# S32K322_M7 register map
Vendor: NXP Semiconductors; File version: 1.0
CPU: CM7 r0p1, little endian, MPU, FPU, VTOR, 4 interrupt priority bits
Registers are 32-bit, read-write, reset 0x0 unless marked. A register's access mark holds for its fields unless they carry their own. Offsets are from the block's base; [hi:lo] are bit positions; lines under a group give offsets from that group; {n}, {i} and the like mark numbered series.

## PIT_0 — PIT
Base 0x400B0000
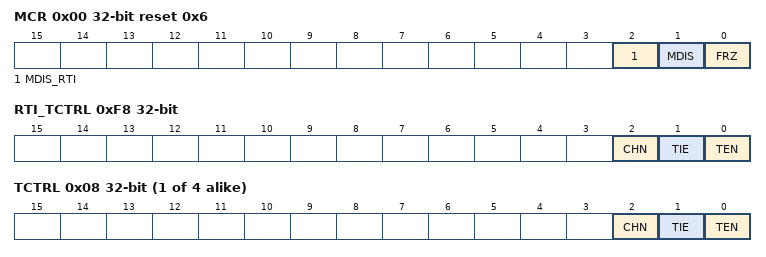
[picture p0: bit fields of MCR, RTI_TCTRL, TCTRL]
0x00 MCR reset 0x6 — PIT Module Control Register
  [2] MDIS_RTI — Module Disable for RTI
    0=t00221 (Clock for RTI timers is enabled); 1=t01881 (Clock for RTI timers is disabled)
  [1] MDIS — Module Disable for PIT
    0=t0301 (Clock for standard PIT timers is enabled.); 1=t00000111 (Clock for standard PIT timers is disabled.)
  [0] FRZ — Freeze
    0=t000001 (Timers continue to run in Debug mode.); 1=t0000011 (Timers are stopped in Debug mode.)
0xE0 LTMR64H ro — PIT Upper Lifetime Timer Register
  [31:0] LTH — Life Timer value
0xE4 LTMR64L ro — PIT Lower Lifetime Timer Register
  [31:0] LTL — Life Timer value
0xEC RTI_LDVAL_STAT write-clears — RTI Timer Load Value Sync Status Register
  [0] RT_STAT write-clears — RTI Timer Load Value Sync Status
    0=t00221112 (RTI_LDVAL register not loaded.); 1=t0022144 (RTI_LDVAL register updated with new value.)
0xF0 RTI_LDVAL — Timer Load Value Register
  [31:0] TSV — Timer Start Value
0xF4 RTI_CVAL ro — Current Timer Value Register
  [31:0] TVL — Current Timer Value
0xF8 RTI_TCTRL — Timer Control Register
  [2] CHN — Chain Mode
  [1] TIE — Timer Interrupt Enable
    0=t0661 (Interrupt requests from the RTI timers are disabled.); 1=t071 (Interrupt is requested whenever TIF is set.)
  [0] TEN — Timer Enable Bit
    0=t0041 (RTI timer is disabled.); 1=t061 (RTI timer is enabled.)
0xFC RTI_TFLG write-1-clears — Timer Flag Register
  [0] TIF write-1-clears — Timer Interrupt Flag
    0=t07321 (Time-out has not yet occurred.); 1=s4071 (Time-out has occurred.)
{0x100+0x10*i} TIMER[{i}] (i=0..3) group
  0x00 LDVAL — Timer Load Value Register
    [31:0] TSV — Timer Start Value
  0x04 CVAL ro — Current Timer Value Register
    [31:0] TVL — Current Timer Value
  0x08 TCTRL — Timer Control Register
    [2] CHN — Chain Mode
      0=timer0001 (Timer is not chained.); 1=timer0081 (Timer is chained to a previous timer. For example, for channel 2, if this field is set, Timer 2 is chained to Timer 1.)
    [1] TIE — Timer Interrupt Enable
      0=t0331 (Interrupt requests from Timer n are disabled.); 1=t077711 (Interrupt is requested whenever TIF is set.)
    [0] TEN — Timer Enable
      0=t02981 (Timer n is disabled.); 1=t008981 (Timer n is enabled.)
  0x0C TFLG write-1-clears — Timer Flag Register
    [0] TIF write-1-clears — Timer Interrupt Flag
      0=t0022331 (Timeout has not yet occurred.); 1=t0022332221 (Timeout has occurred.)

## PIT_1 — PIT
Base 0x400B4000
Same registers: PIT_2 0x402FC000
Registers as PIT_0, without LTMR64H, LTMR64L, RTI_LDVAL_STAT, RTI_LDVAL, RTI_CVAL, RTI_TCTRL, RTI_TFLG; these are added or differ:
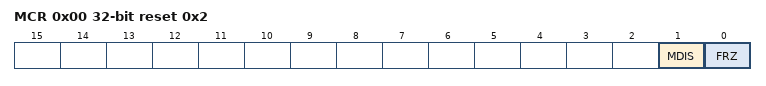
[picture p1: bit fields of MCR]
0x00 MCR reset 0x2 — PIT Module Control Register
  [1] MDIS — Module Disable for PIT
    0=t0301 (Clock for standard PIT timers is enabled.); 1=t00000111 (Clock for standard PIT timers is disabled.)
  [0] FRZ — Freeze
    0=t000001 (Timers continue to run in Debug mode.); 1=t0000011 (Timers are stopped in Debug mode.)

## AXBS_LITE — AXBS
Base 0x40200000
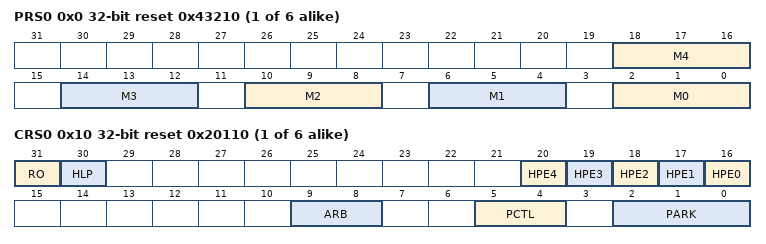
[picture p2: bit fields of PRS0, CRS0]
{0x0+0x100*i} PRS{i} reset 0x43210 (i=0..5) — Priority Slave Registers
  [all] fields
    0=This master has level 1 or highest priority when accessing the slave port; {v}=This master has level {v+1} priority when accessing the slave port (v=1..6); 7=This master has level 8 or lowest priority when accessing the slave port
  [4n+2:4n] M{n} (n=0..4) — Master {n} Priority
{0x10+0x100*i} CRS{i} reset 0x20110 (i=0..5) — Control Register
  [31] RO — Read Only
    0=The CRSn and PRSn registers are writeable; 1=The CRSn and PRSn registers are read-only and cannot be written (attempted writes have no effect on the registers and result in a bus error response)
  [30] HLP — Halt Low Priority
    0=The low-power mode request has the highest priority for arbitration on this slave port; 1=The low-power mode request has the lowest initial priority for arbitration on this slave port
  [n+16] HPE{n} (n=0..4) — High Priority Elevation {n}
    0=Master high-priority elevation for master {n}. is disabled on this slave port.; 1=Master high-priority elevation for master {n}. is enabled on this slave port.
  [9:8] ARB — Arbitration Mode
    0=Fixed priority; 1=Round-robin (rotating) priority
  [5:4] PCTL — Parking Control
    0=When no master makes a request, the arbiter parks the slave port on the master port defined by the PARK bit field; 1=When no master makes a request, the arbiter parks the slave port on the last master to be in control of the slave port; 2=Low-power park. When no master makes a request, the slave port is not parked on a master and the arbiter drives all outputs to a constant safe state.
  [2:0] PARK
    {v}=Park on master port M{v} (v=0..7)

## Notices in the file
Copyright 2016-2021 NXP
NXP Confidential. This software is owned or controlled by NXP and may only be
used strictly in accordance with the applicable license terms. By expressly
accepting such terms or by downloading, installing, activating and/or otherwise
using the software, you are agreeing that you have read, and that you agree to
comply with and are bound by, such license terms. If you do not agree to be
bound by the applicable license terms, then you may not retain, install,
activate or otherwise use the software. The production use license in
Section 2.3 is expressly granted for this software.
